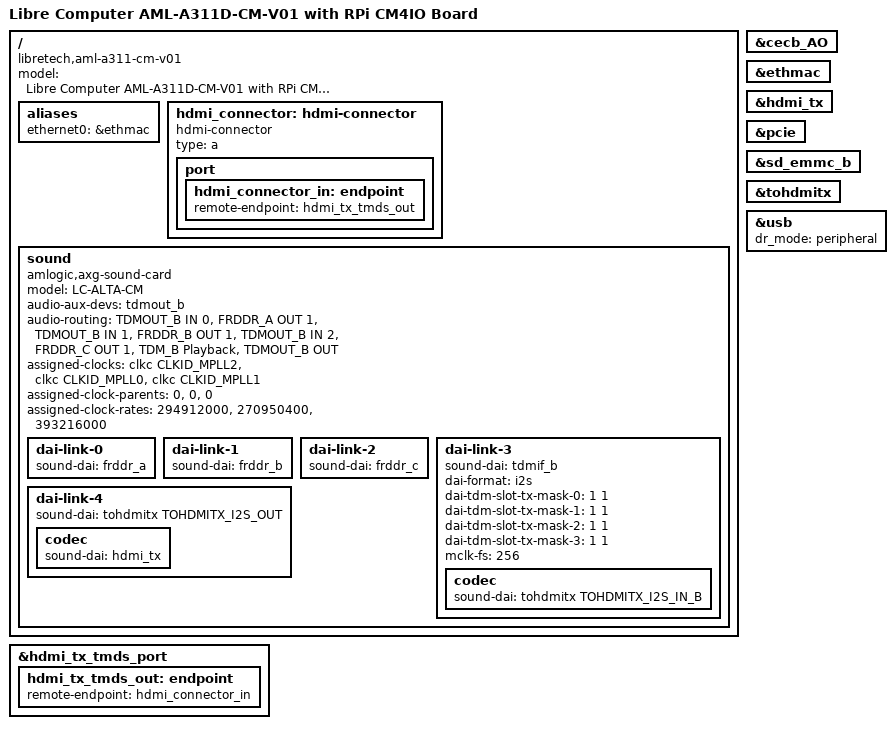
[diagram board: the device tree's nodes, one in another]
// SPDX-License-Identifier: (GPL-2.0+ OR MIT)
/*
 * Copyright (c) 2023 Neil Armstrong <neil.armstrong@linaro.org>
 */

/dts-v1/;

#include "meson-libretech-cottonwood-cm-v01.dtsi"
#include <dt-bindings/input/input.h>
#include <dt-bindings/leds/common.h>
#include <dt-bindings/sound/meson-g12a-tohdmitx.h>

/ {
	compatible = "libretech,aml-a311-cm-v01", "bananapi,bpi-cm4", "amlogic,a311d", "amlogic,g12b";
	model = "Libre Computer AML-A311D-CM-V01 with RPi CM4IO Board";

	aliases {
		ethernet0 = &ethmac;
	};

	hdmi_connector: hdmi-connector {
		compatible = "hdmi-connector";
		type = "a";

		port {
			hdmi_connector_in: endpoint {
				remote-endpoint = <&hdmi_tx_tmds_out>;
			};
		};
	};

	sound {
		compatible = "amlogic,axg-sound-card";
		model = "LC-ALTA-CM";
		audio-aux-devs = <&tdmout_b>;
		audio-routing = "TDMOUT_B IN 0", "FRDDR_A OUT 1",
				"TDMOUT_B IN 1", "FRDDR_B OUT 1",
				"TDMOUT_B IN 2", "FRDDR_C OUT 1",
				"TDM_B Playback", "TDMOUT_B OUT";

		assigned-clocks = <&clkc CLKID_MPLL2>,
				  <&clkc CLKID_MPLL0>,
				  <&clkc CLKID_MPLL1>;
		assigned-clock-parents = <0>, <0>, <0>;
		assigned-clock-rates = <294912000>,
				       <270950400>,
				       <393216000>;

		dai-link-0 {
			sound-dai = <&frddr_a>;
		};

		dai-link-1 {
			sound-dai = <&frddr_b>;
		};

		dai-link-2 {
			sound-dai = <&frddr_c>;
		};

		/* 8ch hdmi interface */
		dai-link-3 {
			sound-dai = <&tdmif_b>;
			dai-format = "i2s";
			dai-tdm-slot-tx-mask-0 = <1 1>;
			dai-tdm-slot-tx-mask-1 = <1 1>;
			dai-tdm-slot-tx-mask-2 = <1 1>;
			dai-tdm-slot-tx-mask-3 = <1 1>;
			mclk-fs = <256>;

			codec {
				sound-dai = <&tohdmitx TOHDMITX_I2S_IN_B>;
			};
		};

		/* hdmi glue */
		dai-link-4 {
			sound-dai = <&tohdmitx TOHDMITX_I2S_OUT>;

			codec {
				sound-dai = <&hdmi_tx>;
			};
		};
	};
};

&cecb_AO {
	status = "okay";
};

&ethmac {
	status = "okay";
};

&hdmi_tx {
	status = "okay";
};

&hdmi_tx_tmds_port {
	hdmi_tx_tmds_out: endpoint {
		remote-endpoint = <&hdmi_connector_in>;
	};
};

&pcie {
	status = "okay";
};

&sd_emmc_b {
	status = "okay";
};

&tohdmitx {
	status = "okay";
};

&usb {
	dr_mode = "peripheral";

	status = "okay";
};
